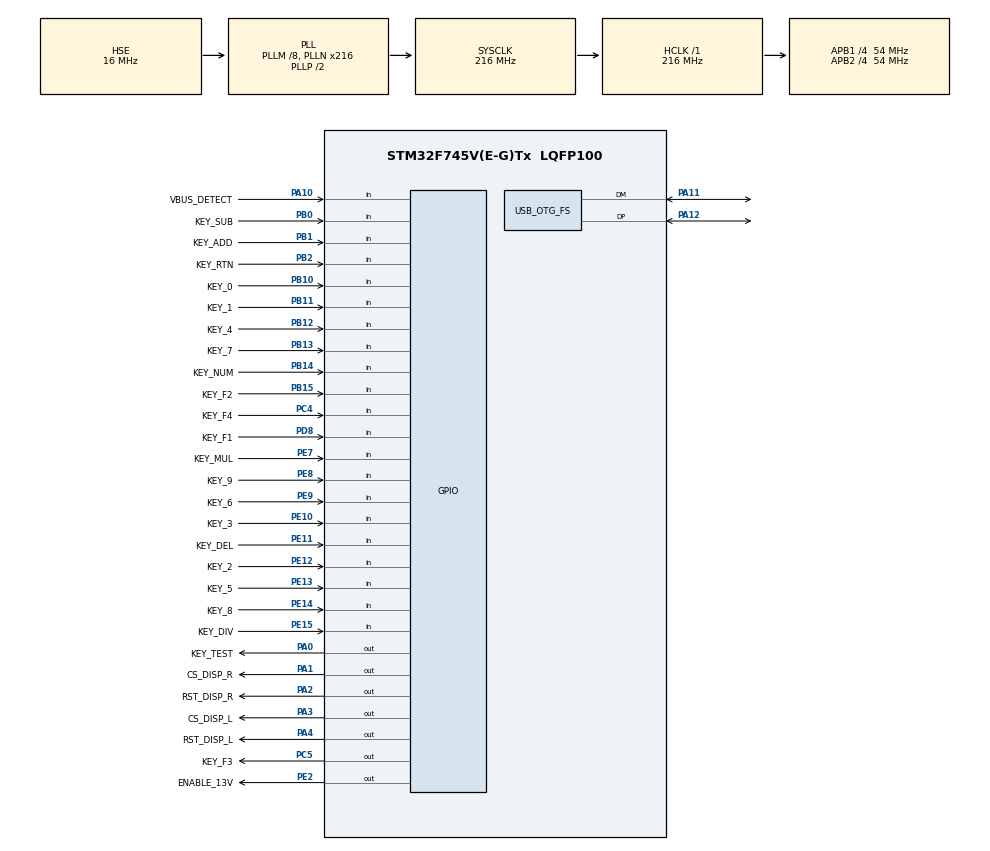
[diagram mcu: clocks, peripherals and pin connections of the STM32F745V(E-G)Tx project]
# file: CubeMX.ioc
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CORTEX_M7.CPU_ICache=Disabled
CORTEX_M7.Enable_Spec=__NULL
CORTEX_M7.MPU_Control=__NULL
CORTEX_M7.default_mode_Activation=1
Mcu.Family=STM32F7
Mcu.Name=STM32F745V(E-G)Tx
Mcu.Package=LQFP100
NVIC.PriorityGroup=NVIC_PRIORITYGROUP_4
NVIC.TIM6_DAC_IRQn=true\:0\:0\:false\:false\:true\:true\:true\:true
PA0/WKUP.GPIO_Label=KEY_TEST
PA0/WKUP.Signal=GPIO_Output
PA1.GPIO_Label=CS_DISP_R
PA1.Signal=GPIO_Output
PA10.GPIO_Label=VBUS_DETECT
PA10.Signal=GPIO_Input
PA11.Mode=Device_Only
PA11.Signal=USB_OTG_FS_DM
PA12.Mode=Device_Only
PA12.Signal=USB_OTG_FS_DP
PA13.Mode=Serial_Wire
PA13.Signal=SYS_JTMS-SWDIO
PA14.Mode=Serial_Wire
PA14.Signal=SYS_JTCK-SWCLK
PA2.GPIO_Label=RST_DISP_R
PA2.Signal=GPIO_Output
PA3.GPIO_Label=CS_DISP_L
PA3.Signal=GPIO_Output
PA4.GPIO_Label=RST_DISP_L
PA4.Signal=GPIO_Output
PA5.Signal=SPI1_SCK
PA6.Signal=SPI1_MISO
PA7.Signal=SPI1_MOSI
PB0.GPIO_Label=KEY_SUB
PB0.Signal=GPIO_Input
PB1.GPIO_Label=KEY_ADD
PB1.Signal=GPIO_Input
PB10.GPIO_Label=KEY_0
PB10.Signal=GPIO_Input
PB11.GPIO_Label=KEY_1
PB11.Signal=GPIO_Input
PB12.GPIO_Label=KEY_4
PB12.Signal=GPIO_Input
PB13.GPIO_Label=KEY_7
PB13.Signal=GPIO_Input
PB14.GPIO_Label=KEY_NUM
PB14.Signal=GPIO_Input
PB15.GPIO_Label=KEY_F2
PB15.Signal=GPIO_Input
PB2.GPIO_Label=KEY_RTN
PB2.Signal=GPIO_Input
PC4.GPIO_Label=KEY_F4
PC4.Signal=GPIO_Input
PC5.GPIO_Label=KEY_F3
PC5.Signal=GPIO_Output
PD8.GPIO_Label=KEY_F1
PD8.Signal=GPIO_Input
PE10.GPIO_Label=KEY_3
PE10.Signal=GPIO_Input
PE11.GPIO_Label=KEY_DEL
PE11.Signal=GPIO_Input
PE12.GPIO_Label=KEY_2
PE12.Signal=GPIO_Input
PE13.GPIO_Label=KEY_5
PE13.Signal=GPIO_Input
PE14.GPIO_Label=KEY_8
PE14.Signal=GPIO_Input
PE15.GPIO_Label=KEY_DIV
PE15.Signal=GPIO_Input
PE2.GPIO_Label=ENABLE_13V
PE2.Signal=GPIO_Output
PE7.GPIO_Label=KEY_MUL
PE7.Signal=GPIO_Input
PE8.GPIO_Label=KEY_9
PE8.Signal=GPIO_Input
PE9.GPIO_Label=KEY_6
PE9.Signal=GPIO_Input
PH0/OSC_IN.Mode=HSE-External-Clock-Source
PH0/OSC_IN.Signal=RCC_OSC_IN
PH1/OSC_OUT.Mode=HSE-External-Clock-Source
PH1/OSC_OUT.Signal=RCC_OSC_OUT
ProjectManager.HeapSize=0x9000
ProjectManager.StackSize=0x9000
ProjectManager.TargetToolchain=CMake
RCC.AHBFreq_Value=216000000
RCC.APB1CLKDivider=RCC_HCLK_DIV4
RCC.APB1Freq_Value=54000000
RCC.APB1TimFreq_Value=108000000
RCC.APB2CLKDivider=RCC_HCLK_DIV4
RCC.APB2Freq_Value=54000000
RCC.APB2TimFreq_Value=108000000
RCC.CortexFreq_Value=216000000
RCC.HCLKFreq_Value=216000000
RCC.HSE_VALUE=16000000
RCC.HSI_VALUE=16000000
RCC.LSE_VALUE=32768
RCC.PLL48CLockSelection=RCC_CLK48SOURCE_PLLSAIP
RCC.PLLM=8
RCC.PLLN=216
RCC.PLLSAIN=96
RCC.PLLSAIP=RCC_PLLSAIP_DIV4
RCC.SYSCLKFreq_VALUE=216000000
RCC.SYSCLKSource=RCC_SYSCLKSOURCE_PLLCLK
RCC.USBFreq_Value=48000000
RCC.VCOOutputFreq_Value=432000000
TIM1.AutoReloadPreload=TIM_AUTORELOAD_PRELOAD_ENABLE
TIM6.AutoReloadPreload=TIM_AUTORELOAD_PRELOAD_ENABLE
TIM6.Period=20000
TIM6.Prescaler=10
TIM6.TIM_MasterOutputTrigger=TIM_TRGO_ENABLE
USB_OTG_FS.VirtualMode=Device_Only
VP_TIM1_VS_ClockSourceINT.Mode=Internal
VP_TIM6_VS_ClockSourceINT.Mode=Enable_Timer
board=custom

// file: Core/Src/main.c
/* USER CODE BEGIN Header */
#include "Calculator.hpp"
/**
 ******************************************************************************
 * @file           : main.c
 * @brief          : Main program body
 ******************************************************************************
 * @attention
 *
 * Copyright (c) 2025 STMicroelectronics.
 * All rights reserved.
 *
 * This software is licensed under terms that can be found in the LICENSE file
 * in the root directory of this software component.
 * If no LICENSE file comes with this software, it is provided AS-IS.
 *
 ******************************************************************************
 */
/* USER CODE END Header */
#include "main.h"

TIM_HandleTypeDef htim1;
TIM_HandleTypeDef htim6;

PCD_HandleTypeDef hpcd_USB_OTG_FS;

void SystemClock_Config(void);
static void MX_GPIO_Init(void);
static void MX_USB_OTG_FS_PCD_Init(void);
static void MX_TIM1_Init(void);
static void MX_TIM6_Init(void);

int main(void)
{

  /* MCU Configuration--------------------------------------------------------*/

  /* Reset of all peripherals, Initializes the Flash interface and the Systick. */
  HAL_Init();

  /* Configure the system clock */
  SystemClock_Config();

  /* Initialize all configured peripherals */
  MX_GPIO_Init();
  MX_USB_OTG_FS_PCD_Init();
  MX_TIM1_Init();
  MX_TIM6_Init();
  /* USER CODE BEGIN 2 */
    CalculatorInit();
  /* USER CODE END 2 */

  /* Infinite loop */
    while (1) {

    /* USER CODE BEGIN 3 */
        Calculator();
    }
  /* USER CODE END 3 */
}

void SystemClock_Config(void)
{
  RCC_OscInitTypeDef RCC_OscInitStruct = {0};
  RCC_ClkInitTypeDef RCC_ClkInitStruct = {0};

  /** Configure the main internal regulator output voltage
  */
  __HAL_RCC_PWR_CLK_ENABLE();
  __HAL_PWR_VOLTAGESCALING_CONFIG(PWR_REGULATOR_VOLTAGE_SCALE1);

  /** Initializes the RCC Oscillators according to the specified parameters
  * in the RCC_OscInitTypeDef structure.
  */
  RCC_OscInitStruct.OscillatorType = RCC_OSCILLATORTYPE_HSE;
  RCC_OscInitStruct.HSEState = RCC_HSE_BYPASS;
  RCC_OscInitStruct.PLL.PLLState = RCC_PLL_ON;
  RCC_OscInitStruct.PLL.PLLSource = RCC_PLLSOURCE_HSE;
  RCC_OscInitStruct.PLL.PLLM = 8;
  RCC_OscInitStruct.PLL.PLLN = 216;
  RCC_OscInitStruct.PLL.PLLP = RCC_PLLP_DIV2;
  RCC_OscInitStruct.PLL.PLLQ = 2;
  if (HAL_RCC_OscConfig(&RCC_OscInitStruct) != HAL_OK)
  {
    Error_Handler();
  }

  /** Activate the Over-Drive mode
  */
  if (HAL_PWREx_EnableOverDrive() != HAL_OK)
  {
    Error_Handler();
  }

  /** Initializes the CPU, AHB and APB buses clocks
  */
  RCC_ClkInitStruct.ClockType = RCC_CLOCKTYPE_HCLK|RCC_CLOCKTYPE_SYSCLK
                              |RCC_CLOCKTYPE_PCLK1|RCC_CLOCKTYPE_PCLK2;
  RCC_ClkInitStruct.SYSCLKSource = RCC_SYSCLKSOURCE_PLLCLK;
  RCC_ClkInitStruct.AHBCLKDivider = RCC_SYSCLK_DIV1;
  RCC_ClkInitStruct.APB1CLKDivider = RCC_HCLK_DIV4;
  RCC_ClkInitStruct.APB2CLKDivider = RCC_HCLK_DIV4;

  if (HAL_RCC_ClockConfig(&RCC_ClkInitStruct, FLASH_LATENCY_7) != HAL_OK)
  {
    Error_Handler();
  }
}

static void MX_TIM1_Init(void)
{

  TIM_ClockConfigTypeDef sClockSourceConfig = {0};
  TIM_MasterConfigTypeDef sMasterConfig = {0};

  htim1.Instance = TIM1;
  htim1.Init.Prescaler = 0;
  htim1.Init.CounterMode = TIM_COUNTERMODE_UP;
  htim1.Init.Period = 65535;
  htim1.Init.ClockDivision = TIM_CLOCKDIVISION_DIV1;
  htim1.Init.RepetitionCounter = 0;
  htim1.Init.AutoReloadPreload = TIM_AUTORELOAD_PRELOAD_ENABLE;
  if (HAL_TIM_Base_Init(&htim1) != HAL_OK)
  {
    Error_Handler();
  }
  sClockSourceConfig.ClockSource = TIM_CLOCKSOURCE_INTERNAL;
  if (HAL_TIM_ConfigClockSource(&htim1, &sClockSourceConfig) != HAL_OK)
  {
    Error_Handler();
  }
  sMasterConfig.MasterOutputTrigger = TIM_TRGO_RESET;
  sMasterConfig.MasterOutputTrigger2 = TIM_TRGO2_RESET;
  sMasterConfig.MasterSlaveMode = TIM_MASTERSLAVEMODE_DISABLE;
  if (HAL_TIMEx_MasterConfigSynchronization(&htim1, &sMasterConfig) != HAL_OK)
  {
    Error_Handler();
  }

}

static void MX_TIM6_Init(void)
{

  TIM_MasterConfigTypeDef sMasterConfig = {0};

  htim6.Instance = TIM6;
  htim6.Init.Prescaler = 10;
  htim6.Init.CounterMode = TIM_COUNTERMODE_UP;
  htim6.Init.Period = 20000;
  htim6.Init.AutoReloadPreload = TIM_AUTORELOAD_PRELOAD_ENABLE;
  if (HAL_TIM_Base_Init(&htim6) != HAL_OK)
  {
    Error_Handler();
  }
  sMasterConfig.MasterOutputTrigger = TIM_TRGO_ENABLE;
  sMasterConfig.MasterSlaveMode = TIM_MASTERSLAVEMODE_DISABLE;
  if (HAL_TIMEx_MasterConfigSynchronization(&htim6, &sMasterConfig) != HAL_OK)
  {
    Error_Handler();
  }

}

static void MX_USB_OTG_FS_PCD_Init(void)
{

  hpcd_USB_OTG_FS.Instance = USB_OTG_FS;
  hpcd_USB_OTG_FS.Init.dev_endpoints = 6;
  hpcd_USB_OTG_FS.Init.speed = PCD_SPEED_FULL;
  hpcd_USB_OTG_FS.Init.dma_enable = DISABLE;
  hpcd_USB_OTG_FS.Init.phy_itface = PCD_PHY_EMBEDDED;
  hpcd_USB_OTG_FS.Init.Sof_enable = DISABLE;
  hpcd_USB_OTG_FS.Init.low_power_enable = DISABLE;
  hpcd_USB_OTG_FS.Init.lpm_enable = DISABLE;
  hpcd_USB_OTG_FS.Init.vbus_sensing_enable = DISABLE;
  hpcd_USB_OTG_FS.Init.use_dedicated_ep1 = DISABLE;
  if (HAL_PCD_Init(&hpcd_USB_OTG_FS) != HAL_OK)
  {
    Error_Handler();
  }

}

static void MX_GPIO_Init(void)
{
  GPIO_InitTypeDef GPIO_InitStruct = {0};

  /* GPIO Ports Clock Enable */
  __HAL_RCC_GPIOE_CLK_ENABLE();
  __HAL_RCC_GPIOH_CLK_ENABLE();
  __HAL_RCC_GPIOA_CLK_ENABLE();
  __HAL_RCC_GPIOC_CLK_ENABLE();
  __HAL_RCC_GPIOB_CLK_ENABLE();
  __HAL_RCC_GPIOD_CLK_ENABLE();

  /*Configure GPIO pin Output Level */
  HAL_GPIO_WritePin(ENABLE_13V_GPIO_Port, ENABLE_13V_Pin, GPIO_PIN_RESET);

  /*Configure GPIO pin Output Level */
  HAL_GPIO_WritePin(GPIOA, KEY_TEST_Pin|CS_DISP_R_Pin|RST_DISP_R_Pin|CS_DISP_L_Pin
                          |RST_DISP_L_Pin, GPIO_PIN_RESET);

  /*Configure GPIO pin Output Level */
  HAL_GPIO_WritePin(KEY_F3_GPIO_Port, KEY_F3_Pin, GPIO_PIN_RESET);

  /*Configure GPIO pin : ENABLE_13V_Pin */
  GPIO_InitStruct.Pin = ENABLE_13V_Pin;
  GPIO_InitStruct.Mode = GPIO_MODE_OUTPUT_PP;
  GPIO_InitStruct.Pull = GPIO_NOPULL;
  GPIO_InitStruct.Speed = GPIO_SPEED_FREQ_LOW;
  HAL_GPIO_Init(ENABLE_13V_GPIO_Port, &GPIO_InitStruct);

  /*Configure GPIO pins : KEY_TEST_Pin CS_DISP_R_Pin RST_DISP_R_Pin CS_DISP_L_Pin
                           RST_DISP_L_Pin */
  GPIO_InitStruct.Pin = KEY_TEST_Pin|CS_DISP_R_Pin|RST_DISP_R_Pin|CS_DISP_L_Pin
                          |RST_DISP_L_Pin;
  GPIO_InitStruct.Mode = GPIO_MODE_OUTPUT_PP;
  GPIO_InitStruct.Pull = GPIO_NOPULL;
  GPIO_InitStruct.Speed = GPIO_SPEED_FREQ_LOW;
  HAL_GPIO_Init(GPIOA, &GPIO_InitStruct);

  /*Configure GPIO pins : PA5 PA6 PA7 */
  GPIO_InitStruct.Pin = GPIO_PIN_5|GPIO_PIN_6|GPIO_PIN_7;
  GPIO_InitStruct.Mode = GPIO_MODE_AF_PP;
  GPIO_InitStruct.Pull = GPIO_NOPULL;
  GPIO_InitStruct.Speed = GPIO_SPEED_FREQ_VERY_HIGH;
  GPIO_InitStruct.Alternate = GPIO_AF5_SPI1;
  HAL_GPIO_Init(GPIOA, &GPIO_InitStruct);

  /*Configure GPIO pin : KEY_F4_Pin */
  GPIO_InitStruct.Pin = KEY_F4_Pin;
  GPIO_InitStruct.Mode = GPIO_MODE_INPUT;
  GPIO_InitStruct.Pull = GPIO_NOPULL;
  HAL_GPIO_Init(KEY_F4_GPIO_Port, &GPIO_InitStruct);

  /*Configure GPIO pin : KEY_F3_Pin */
  GPIO_InitStruct.Pin = KEY_F3_Pin;
  GPIO_InitStruct.Mode = GPIO_MODE_OUTPUT_PP;
  GPIO_InitStruct.Pull = GPIO_NOPULL;
  GPIO_InitStruct.Speed = GPIO_SPEED_FREQ_LOW;
  HAL_GPIO_Init(KEY_F3_GPIO_Port, &GPIO_InitStruct);

  /*Configure GPIO pins : KEY_SUB_Pin KEY_ADD_Pin KEY_RTN_Pin KEY_0_Pin
                           KEY_1_Pin KEY_4_Pin KEY_7_Pin KEY_NUM_Pin
                           KEY_F2_Pin */
  GPIO_InitStruct.Pin = KEY_SUB_Pin|KEY_ADD_Pin|KEY_RTN_Pin|KEY_0_Pin
                          |KEY_1_Pin|KEY_4_Pin|KEY_7_Pin|KEY_NUM_Pin
                          |KEY_F2_Pin;
  GPIO_InitStruct.Mode = GPIO_MODE_INPUT;
  GPIO_InitStruct.Pull = GPIO_NOPULL;
  HAL_GPIO_Init(GPIOB, &GPIO_InitStruct);

  /*Configure GPIO pins : KEY_MUL_Pin KEY_9_Pin KEY_6_Pin KEY_3_Pin
                           KEY_DEL_Pin KEY_2_Pin KEY_5_Pin KEY_8_Pin
                           KEY_DIV_Pin */
  GPIO_InitStruct.Pin = KEY_MUL_Pin|KEY_9_Pin|KEY_6_Pin|KEY_3_Pin
                          |KEY_DEL_Pin|KEY_2_Pin|KEY_5_Pin|KEY_8_Pin
                          |KEY_DIV_Pin;
  GPIO_InitStruct.Mode = GPIO_MODE_INPUT;
  GPIO_InitStruct.Pull = GPIO_NOPULL;
  HAL_GPIO_Init(GPIOE, &GPIO_InitStruct);

  /*Configure GPIO pin : KEY_F1_Pin */
  GPIO_InitStruct.Pin = KEY_F1_Pin;
  GPIO_InitStruct.Mode = GPIO_MODE_INPUT;
  GPIO_InitStruct.Pull = GPIO_NOPULL;
  HAL_GPIO_Init(KEY_F1_GPIO_Port, &GPIO_InitStruct);

  /*Configure GPIO pin : VBUS_DETECT_Pin */
  GPIO_InitStruct.Pin = VBUS_DETECT_Pin;
  GPIO_InitStruct.Mode = GPIO_MODE_INPUT;
  GPIO_InitStruct.Pull = GPIO_NOPULL;
  HAL_GPIO_Init(VBUS_DETECT_GPIO_Port, &GPIO_InitStruct);

}

void Error_Handler(void)
{
    __disable_irq();
    while (1) {
    }
}
